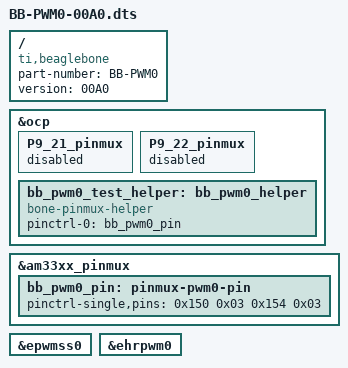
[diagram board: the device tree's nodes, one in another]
/*
 * Copyright (C) 2016 Seeed Studio.
 *
 * This program is free software; you can redistribute it and/or modify
 * it under the terms of the GNU General Public License version 2 as
 * published by the Free Software Foundation.
 */

/dts-v1/;
/plugin/;

#include <dt-bindings/gpio/gpio.h>
#include <dt-bindings/pinctrl/am33xx.h>

/{
	compatible = "ti,beaglebone", "ti,beaglebone-black", "ti,beaglebone-green";
	part-number = "BB-PWM0";
	version = "00A0";

	/*
	 * Free up the pins used by the cape from the pinmux helpers.
	 */
	fragment@0 {
		target = <&ocp>;
		__overlay__ {
			P9_21_pinmux { status = "disabled"; };	/* (B17) spi0_d0.ehrpwm0B */
			P9_22_pinmux { status = "disabled"; };	/* (A17) spi0_sclk.ehrpwm0A */
		};
	};

	fragment@1 {
		target = <&am33xx_pinmux>;
		__overlay__ {
			bb_pwm0_pin: pinmux-pwm0-pin {
				pinctrl-single,pins = <
					0x150 0x03 /* (A17) spi0_sclk.ehrpwm0A */
					0x154 0x03 /* (B17) spi0_d0.ehrpwm0B */
				>;
			};
		};
	};

	fragment@2 {
		target = <&ocp>;
		__overlay__ {
			bb_pwm0_test_helper: bb_pwm0_helper {
				compatible = "bone-pinmux-helper";
				pinctrl-names = "default";
				pinctrl-0 = <&bb_pwm0_pin>;
				status = "okay";
			};
		};
	};

	fragment@3 {
		target = <&epwmss0>;
		__overlay__ {
			status = "okay";
		};
	};

	fragment@4 {
		target = <&ehrpwm0>;
		__overlay__ {
			status = "okay";
		};
	};
};
